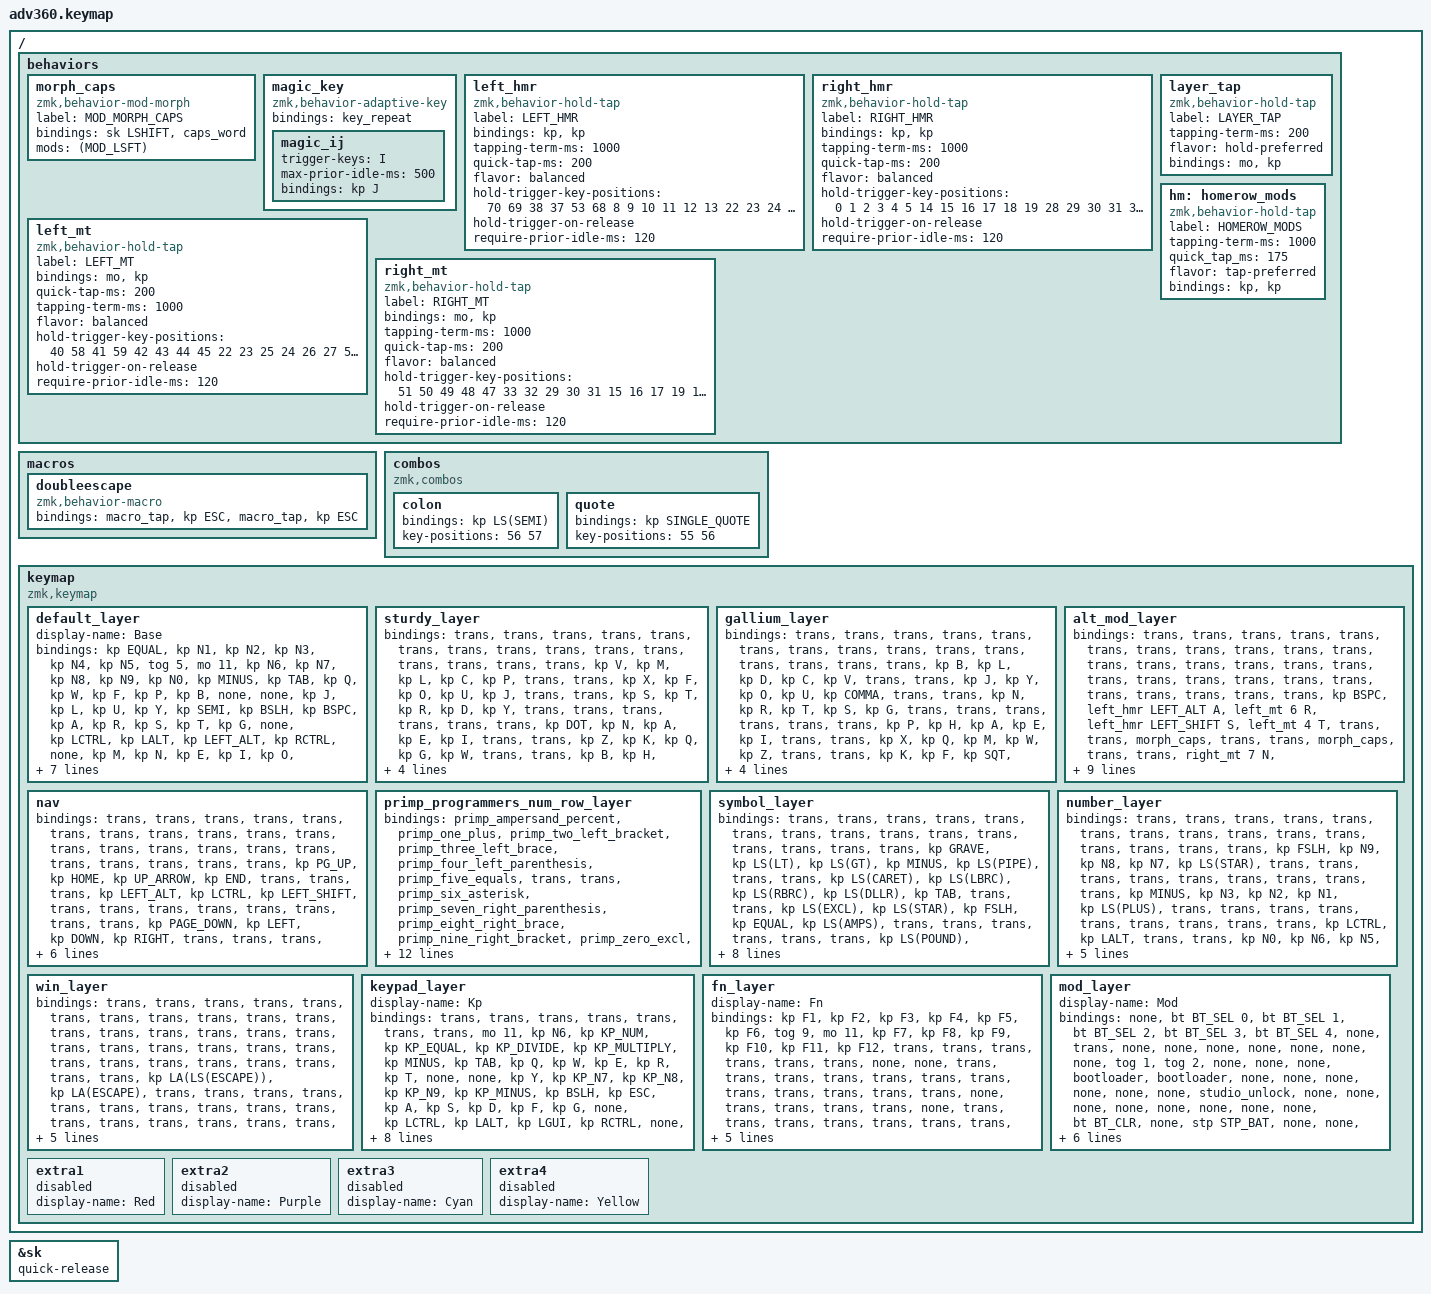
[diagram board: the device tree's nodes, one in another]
#include <dt-bindings/zmk/stp.h>
#include <behaviors.dtsi>
#include <dt-bindings/zmk/backlight.h>
#include <dt-bindings/zmk/bt.h>
#include <dt-bindings/zmk/keys.h>
#include <dt-bindings/zmk/rgb.h>

&sk { quick-release; };

#define BASE 0
#define STURDY 1
#define GALLIUM 2
#define ALT_MOD 3
#define PROGRAMMERS_DVORAK 4
#define PRIMP_PROGRAMMERS 5
#define SYMBOL_LAYER 6
#define KEY 7
#define FN 8
#define MOD 9

/ {
    behaviors {
        #include "macros.dtsi"
        #include "extra_morphs.dtsi"
        #include "version.dtsi"

        morph_caps: morph_caps {
            compatible = "zmk,behavior-mod-morph";
            label = "MOD_MORPH_CAPS";
            #binding-cells = <0>;
            bindings = <&sk LSHIFT>, <&caps_word>;

            mods = <(MOD_LSFT)>;
        };

        magic_key: magic_key {
            compatible = "zmk,behavior-adaptive-key";
            #binding-cells = <0>;
            bindings = <&key_repeat>;

            magic_ij {
                trigger-keys = <I>;
                max-prior-idle-ms = <500>;
                bindings = <&kp J>;
            };
        };

        left_hmr: left_hmr {
            compatible = "zmk,behavior-hold-tap";
            label = "LEFT_HMR";
            bindings = <&kp>, <&kp>;

            #binding-cells = <2>;
            tapping-term-ms = <1000>;
            quick-tap-ms = <200>;
            flavor = "balanced";
            hold-trigger-key-positions = <70 69 38 37 53 68 8 9 10 11 12 13 22 23 24 25 26 27 40 41 42 43 44 45 54 55 56 57 58 59 71 72 73 74 75 65 66>;
            hold-trigger-on-release;
            require-prior-idle-ms = <120>;
        };

        right_hmr: right_hmr {
            compatible = "zmk,behavior-hold-tap";
            label = "RIGHT_HMR";
            bindings = <&kp>, <&kp>;

            #binding-cells = <2>;
            tapping-term-ms = <1000>;
            quick-tap-ms = <200>;
            flavor = "balanced";
            hold-trigger-key-positions = <0 1 2 3 4 5 14 15 16 17 18 19 28 29 30 31 32 33 46 47 48 49 50 51 60 61 62 63 64 65 35 36 52 64 65 66 67 69 70>;
            hold-trigger-on-release;
            require-prior-idle-ms = <120>;
        };

        left_mt: left_mt {
            compatible = "zmk,behavior-hold-tap";
            label = "LEFT_MT";
            bindings = <&mo>, <&kp>;

            #binding-cells = <2>;
            quick-tap-ms = <200>;
            tapping-term-ms = <1000>;
            flavor = "balanced";
            hold-trigger-key-positions = <40 58 41 59 42 43 44 45 22 23 25 24 26 27 57 56 55 54 71 72 73 74 75 66 69 65 70>;
            hold-trigger-on-release;
            require-prior-idle-ms = <120>;
        };

        right_mt: right_mt {
            compatible = "zmk,behavior-hold-tap";
            label = "RIGHT_MT";
            bindings = <&mo>, <&kp>;

            #binding-cells = <2>;
            tapping-term-ms = <1000>;
            quick-tap-ms = <200>;
            flavor = "balanced";
            hold-trigger-key-positions = <51 50 49 48 47 33 32 29 30 31 15 16 17 19 18 64 63 62 61 60 46 28 14 69 66 65 70>;
            hold-trigger-on-release;
            require-prior-idle-ms = <120>;
        };

        layer_tap: layer_tap {
            compatible = "zmk,behavior-hold-tap";
            label = "LAYER_TAP";
            #binding-cells = <2>;
            tapping-term-ms = <200>;
            flavor = "hold-preferred";
            bindings = <&mo>, <&kp>;
        };

        hm: homerow_mods {
            compatible = "zmk,behavior-hold-tap";
            label = "HOMEROW_MODS";
            #binding-cells = <2>;
            tapping-term-ms = <1000>;
            quick_tap_ms = <175>;
            flavor = "tap-preferred";
            bindings = <&kp>, <&kp>;
        };
    };

    macros {
        doubleescape: doubleescape {
            compatible = "zmk,behavior-macro";
            #binding-cells = <0>;
            bindings = <&macro_tap>, <&kp ESC>, <&macro_tap>, <&kp ESC>;
        };
    };

    combos {
        compatible = "zmk,combos";

        colon {
            bindings = <&kp LS(SEMI)>;
            key-positions = <56 57>;
        };

        quote {
            bindings = <&kp SINGLE_QUOTE>;
            key-positions = <55 56>;
        };
    };

    keymap {
        compatible = "zmk,keymap";

        default_layer {
            display-name = "Base";
            bindings = <
&kp EQUAL    &kp N1     &kp N2    &kp N3    &kp N4     &kp N5  &tog 5                                                               &mo 11     &kp N6  &kp N7    &kp N8        &kp N9      &kp N0     &kp MINUS
&kp TAB      &kp Q      &kp W     &kp F     &kp P      &kp B   &none                                                                &none      &kp J   &kp L     &kp U         &kp Y       &kp SEMI   &kp BSLH
&kp BSPC     &kp A      &kp R     &kp S     &kp T      &kp G   &none       &kp LCTRL  &kp LALT           &kp LEFT_ALT   &kp RCTRL   &none      &kp M   &kp N     &kp E         &kp I       &kp O      &kp MINUS
&morph_caps  &kp Z      &kp X     &kp C     &kp D      &kp V                          &kp DELETE         &kp RGUI                              &kp K   &kp H     &kp COMMA     &kp PERIOD  &kp SLASH  &morph_caps
&mo 10       &kp GRAVE  &kp CAPS  &kp LEFT  &kp RIGHT          &magic_key  &kp ESC    &kp LG(GRAVE)      &kp LS(MINUS)  &kp RETURN  &kp SPACE          &kp DOWN  &kp UP_ARROW  &kp LBKT    &kp RBKT   &mo 10
            >;
        };

        sturdy_layer {
            bindings = <
&trans  &trans  &trans  &trans  &trans  &trans  &trans                                      &trans  &trans   &trans  &trans   &trans    &trans     &trans
&trans  &kp V   &kp M   &kp L   &kp C   &kp P   &trans                                      &trans  &kp X    &kp F   &kp O    &kp U     &kp J      &trans
&trans  &kp S   &kp T   &kp R   &kp D   &kp Y   &trans  &trans  &trans      &trans  &trans  &trans  &kp DOT  &kp N   &kp A    &kp E     &kp I      &trans
&trans  &kp Z   &kp K   &kp Q   &kp G   &kp W                   &trans      &trans                  &kp B    &kp H   &kp SQT  &kp SEMI  &kp COMMA  &trans
&trans  &trans  &trans  &trans  &trans          &trans  &trans  &trans      &trans  &trans  &trans           &trans  &trans   &trans    &trans     &trans
            >;
        };

        gallium_layer {
            bindings = <
&trans  &trans  &trans  &trans  &trans  &trans  &trans                                      &trans  &trans  &trans  &trans   &trans    &trans     &trans
&trans  &kp B   &kp L   &kp D   &kp C   &kp V   &trans                                      &trans  &kp J   &kp Y   &kp O    &kp U     &kp COMMA  &trans
&trans  &kp N   &kp R   &kp T   &kp S   &kp G   &trans  &trans  &trans      &trans  &trans  &trans  &kp P   &kp H   &kp A    &kp E     &kp I      &trans
&trans  &kp X   &kp Q   &kp M   &kp W   &kp Z                   &trans      &trans                  &kp K   &kp F   &kp SQT  &kp SEMI  &kp DOT    &trans
&trans  &trans  &trans  &trans  &trans          &trans  &trans  &trans      &trans  &trans  &trans          &trans  &trans   &trans    &trans     &trans
            >;
        };

        alt_mod_layer {
            bindings = <
&trans        &trans                &trans        &trans                  &trans             &trans  &trans                                                &trans  &trans  &trans              &trans                    &trans              &trans                 &trans
&trans        &trans                &trans        &trans                  &trans             &trans  &trans                                                &trans  &trans  &trans              &trans                    &trans              &trans                 &trans
&kp BSPC      &left_hmr LEFT_ALT A  &left_mt 6 R  &left_hmr LEFT_SHIFT S  &left_mt 4 T       &trans  &trans  &morph_caps  &trans      &trans  &morph_caps  &trans  &trans  &right_mt 7 N       &right_hmr RIGHT_SHIFT E  &right_mt 6 I       &right_hmr LEFT_ALT O  &trans
&kp LS(SEMI)  &trans                &trans        &trans                  &left_hmr LCTRL D  &trans                       &trans      &trans                       &trans  &right_hmr RCTRL H  &trans                    &right_mt 8 PERIOD  &trans                 &kp RETURN
&trans        &trans                &trans        &trans                  &trans                     &trans  &trans       &trans      &trans  &trans       &trans          &trans              &trans                    &trans              &trans                 &trans
            >;
        };

        nav {
            bindings = <
&trans  &trans        &trans     &trans          &trans  &trans  &trans                                      &trans  &trans         &trans    &trans        &trans         &trans  &trans
&trans  &trans        &trans     &trans          &trans  &trans  &trans                                      &trans  &kp PG_UP      &kp HOME  &kp UP_ARROW  &kp END        &trans  &trans
&trans  &kp LEFT_ALT  &kp LCTRL  &kp LEFT_SHIFT  &trans  &trans  &trans  &trans  &trans      &trans  &trans  &trans  &kp PAGE_DOWN  &kp LEFT  &kp DOWN      &kp RIGHT      &trans  &trans
&trans  &trans        &trans     &trans          &trans  &trans                  &trans      &trans                  &trans         &kp TAB   &kp LC(LEFT)  &kp LC(RIGHT)  &trans  &trans
&trans  &trans        &trans     &trans          &trans          &trans  &trans  &trans      &trans  &trans  &trans                 &trans    &trans        &trans         &trans  &trans
            >;
        };

        primp_programmers_num_row_layer {
            bindings = <
&primp_ampersand_percent  &primp_one_plus      &primp_two_left_bracket  &primp_three_left_brace  &primp_four_left_parenthesis  &primp_five_equals  &trans                                      &trans  &primp_six_asterisk  &primp_seven_right_parenthesis  &primp_eight_right_brace  &primp_nine_right_bracket  &primp_zero_excl  &primp_hash_grave
&trans                    &trans               &trans                   &trans                   &trans                        &trans              &trans                                      &trans  &trans               &trans                          &trans                    &trans                     &trans            &trans
&trans                    &trans               &trans                   &trans                   &trans                        &trans              &trans  &trans  &trans      &trans  &trans  &trans  &trans               &trans                          &trans                    &trans                     &trans            &trans
&trans                    &trans               &trans                   &trans                   &trans                        &trans                              &trans      &trans                  &trans               &trans                          &trans                    &trans                     &trans            &trans
&trans                    &primp_dollar_tilde  &trans                   &trans                   &trans                                            &trans  &trans  &trans      &trans  &trans  &trans                       &trans                          &trans                    &kp SLASH                  &primp_at_caret   &trans
            >;
        };

        symbol_layer {
            bindings = <
&trans  &trans         &trans        &trans      &trans     &trans         &trans                                         &trans  &trans         &trans         &trans        &trans        &trans       &trans
&trans  &kp GRAVE      &kp LS(LT)    &kp LS(GT)  &kp MINUS  &kp LS(PIPE)   &trans                                         &trans  &kp LS(CARET)  &kp LS(LBRC)   &kp LS(RBRC)  &kp LS(DLLR)  &kp TAB      &trans
&trans  &kp LS(EXCL)   &kp LS(STAR)  &kp FSLH    &kp EQUAL  &kp LS(AMPS)   &trans  &trans  &trans         &trans  &trans  &trans  &kp LS(POUND)  &kp LS(LPAR)   &kp LS(RPAR)  &kp SEMI      &kp LS(DQT)  &trans
&trans  &kp LS(GRAVE)  &kp LS(PLUS)  &kp LBKT    &kp RBKT   &kp LS(PRCNT)                  &kp SPACE      &trans                  &kp LS(AT)     &kp LS(COLON)  &kp COMMA     &kp DOT       &kp SQT      &trans
&trans  &trans         &trans        &trans      &trans                    &trans  &trans  &trans         &trans  &trans  &trans                 &trans         &trans        &trans        &trans       &trans
            >;
        };

        number_layer {
            bindings = <
&trans  &trans     &trans  &trans  &trans  &trans         &trans                                      &trans  &trans  &trans  &trans  &trans     &trans    &trans
&trans  &kp FSLH   &kp N9  &kp N8  &kp N7  &kp LS(STAR)   &trans                                      &trans  &trans  &trans  &trans  &trans     &trans    &trans
&trans  &kp MINUS  &kp N3  &kp N2  &kp N1  &kp LS(PLUS)   &trans  &trans  &trans      &trans  &trans  &trans  &trans  &trans  &trans  &kp LCTRL  &kp LALT  &trans
&trans  &kp N0     &kp N6  &kp N5  &kp N4  &kp LS(PRCNT)                  &trans      &trans                  &trans  &trans  &trans  &trans     &trans    &trans
&trans  &trans     &trans  &trans  &trans                 &trans  &trans  &trans      &trans  &trans  &trans          &trans  &trans  &trans     &trans    &trans
            >;
        };

        win_layer {
            bindings = <
&trans  &trans  &trans  &trans              &trans             &trans  &trans                                      &trans  &trans  &trans  &trans  &trans  &trans  &trans
&trans  &trans  &trans  &trans              &trans             &trans  &trans                                      &trans  &trans  &trans  &trans  &trans  &trans  &trans
&trans  &trans  &trans  &kp LA(LS(ESCAPE))  &kp LA(ESCAPE)     &trans  &trans  &trans  &trans      &trans  &trans  &trans  &trans  &trans  &trans  &trans  &trans  &trans
&trans  &trans  &trans  &kp LG(LC(LEFT))    &kp LG(LC(RIGHT))  &trans                  &trans      &trans                  &trans  &trans  &trans  &trans  &trans  &trans
&trans  &trans  &trans  &trans              &trans                     &trans  &trans  &trans      &trans  &trans  &trans          &trans  &trans  &trans  &trans  &trans
            >;
        };

        keypad_layer {
            display-name = "Kp";
            bindings = <
&trans     &trans     &trans    &trans    &trans     &trans  &trans                                                   &mo 11     &kp N6  &kp KP_NUM  &kp KP_EQUAL  &kp KP_DIVIDE  &kp KP_MULTIPLY  &kp MINUS
&kp TAB    &kp Q      &kp W     &kp E     &kp R      &kp T   &none                                                    &none      &kp Y   &kp KP_N7   &kp KP_N8     &kp KP_N9      &kp KP_MINUS     &kp BSLH
&kp ESC    &kp A      &kp S     &kp D     &kp F      &kp G   &none     &kp LCTRL  &kp LALT      &kp LGUI   &kp RCTRL  &none      &kp H   &kp KP_N4   &kp KP_N5     &kp KP_N6      &kp KP_PLUS      &kp SQT
&kp LSHFT  &kp Z      &kp X     &kp C     &kp V      &kp B                        &kp HOME      &kp PG_UP                        &kp N   &kp KP_N1   &kp KP_N2     &kp KP_N3      &kp KP_ENTER     &kp RSHFT
&mo 10     &kp GRAVE  &kp CAPS  &kp LEFT  &kp RIGHT          &kp BSPC  &kp DEL    &kp END       &kp PG_DN  &kp ENTER  &kp KP_N0          &kp UP      &kp DOWN      &kp KP_DOT     &kp RBKT         &mo 10
            >;
        };

        fn_layer {
            display-name = "Fn";
            bindings = <
&kp F1  &kp F2  &kp F3  &kp F4  &kp F5  &kp F6  &tog 9                                      &mo 11  &kp F7  &kp F8  &kp F9  &kp F10  &kp F11  &kp F12
&trans  &trans  &trans  &trans  &trans  &trans  &none                                       &none   &trans  &trans  &trans  &trans   &trans   &trans
&trans  &trans  &trans  &trans  &trans  &trans  &none   &trans  &trans      &trans  &trans  &none   &trans  &trans  &trans  &trans   &trans   &trans
&trans  &trans  &trans  &trans  &trans  &trans                  &trans      &trans                  &trans  &trans  &trans  &trans   &trans   &trans
&trans  &trans  &trans  &trans  &trans          &trans  &trans  &trans      &trans  &trans  &trans          &trans  &trans  &trans   &trans   &trans
            >;
        };

        mod_layer {
            display-name = "Mod";
            bindings = <
&none           &bt BT_SEL 0  &bt BT_SEL 1  &bt BT_SEL 2  &bt BT_SEL 3  &bt BT_SEL 4  &none                                                  &trans           &none  &none       &none       &none  &none  &none
&none           &tog 1        &tog 2        &none         &none         &none         &bootloader                                            &bootloader      &none  &none       &none       &none  &none  &none
&studio_unlock  &none         &none         &none         &none         &none         &none        &none  &none      &bt BT_CLR  &none       &stp STP_BAT     &none  &none       &none       &none  &none  &none
&none           &tog 3        &tog 4        &tog 5        &macro_ver    &none                             &none      &none                                    &none  &none       &none       &none  &none  &none
&none           &none         &none         &none         &none                       &none        &none  &none      &none       &bl BL_TOG  &rgb_ug RGB_TOG         &bl BL_INC  &bl BL_DEC  &none  &none  &none
            >;
        };

        extra1 {
            display-name = "Red";
            status = "reserved";
        };

        extra2 {
            display-name = "Purple";
            status = "reserved";
        };

        extra3 {
            display-name = "Cyan";
            status = "reserved";
        };

        extra4 {
            display-name = "Yellow";
            status = "reserved";
        };
    };
};
